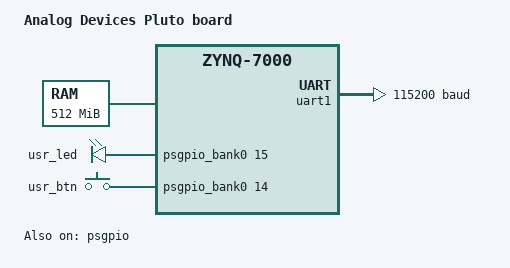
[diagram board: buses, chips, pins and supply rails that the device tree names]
/*
 * Copyright (c) 2023 Brett Witherspoon
 *
 * SPDX-License-Identifier: Apache-2.0
 */

/dts-v1/;
#include <xilinx/zynq7000.dtsi>
#include <zephyr/dt-bindings/gpio/gpio.h>

#include "pluto-pinctrl.dtsi"

/ {
	model = "Analog Devices Pluto board";
	compatible = "adi,pluto", "xlnx,zynq-7000";

	#address-cells = <1>;
	#size-cells = <1>;

	chosen {
		zephyr,sram = &sram0;
		zephyr,console = &uart1;
		zephyr,shell-uart = &uart1;
		zephyr,ocm = &ocm_high;
	};

	aliases {
		led0 = &usr_led;
		sw0 = &usr_btn;
	};

	cpus {
		#address-cells = <1>;
		#size-cells = <0>;

		cpu0: cpu@0 {
			device_type = "cpu";
			compatible = "arm,cortex-a9";
			reg = <0>;
		};

	};

	sram0: memory@0 {
		compatible = "mmio-sram";
		reg = <0x00000000 DT_SIZE_M(512)>;
	};

	leds {
		compatible = "gpio-leds";
		usr_led: usr_led {
			gpios = <&psgpio_bank0 15 GPIO_ACTIVE_HIGH>;
		};
	};

	gpio_keys {
		compatible = "gpio-keys";
		usr_btn: usr_btn {
			gpios = <&psgpio_bank0 14 GPIO_ACTIVE_HIGH>;
		};
	};
};

&uart1 {
	status = "okay";
	current-speed = <115200>;
	clock-frequency = <100000000>;
	pinctrl-0 = <&pinctrl_uart1_default>;
	pinctrl-names = "default";
};

&psgpio {
	status = "okay";
};
